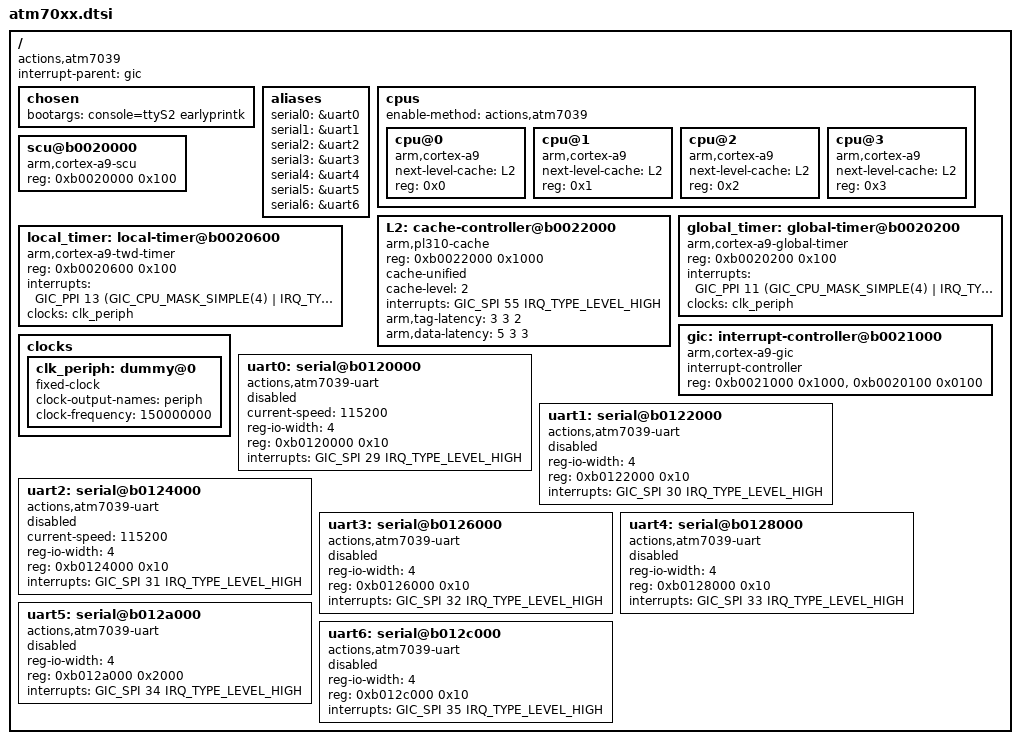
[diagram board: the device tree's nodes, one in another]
/*
 * Copyright (c) 2014 Actions Semiconductor Co., Ltd.
 *
 * Author: Yixun Lan <yixun.lan@gmail.com>
 *
 * This program is free software; you can redistribute it and/or modify
 * it under the terms of the GNU General Public License as published by
 * the Free Software Foundation; either version 2 of the License, or
 * (at your option) any later version.
 *
 * This program is distributed in the hope that it will be useful,
 * but WITHOUT ANY WARRANTY; without even the implied warranty of
 * MERCHANTABILITY or FITNESS FOR A PARTICULAR PURPOSE.  See the
 * GNU General Public License for more details.
 */

#include <dt-bindings/interrupt-controller/irq.h>
#include <dt-bindings/interrupt-controller/arm-gic.h>
#include "skeleton.dtsi"

/ {
	compatible = "actions,atm7039", "actions,atm7059";
	interrupt-parent = <&gic>;

	chosen {
		bootargs = "console=ttyS2 earlyprintk";
	};

	aliases {
		serial0 = &uart0;
		serial1 = &uart1;
		serial2 = &uart2;
		serial3 = &uart3;
		serial4 = &uart4;
		serial5 = &uart5;
		serial6 = &uart6;
	};

	cpus {
		#address-cells = <1>;
		#size-cells = <0>;
		enable-method = "actions,atm7039";

		cpu@0 {
			device_type = "cpu";
			compatible = "arm,cortex-a9";
			next-level-cache = <&L2>;
			reg = <0x0>;
		};
		cpu@1 {
			device_type = "cpu";
			compatible = "arm,cortex-a9";
			next-level-cache = <&L2>;
			reg = <0x1>;
		};
		cpu@2 {
			device_type = "cpu";
			compatible = "arm,cortex-a9";
			next-level-cache = <&L2>;
			reg = <0x2>;
		};
		cpu@3 {
			device_type = "cpu";
			compatible = "arm,cortex-a9";
			next-level-cache = <&L2>;
			reg = <0x3>;
		};
	};

	L2: cache-controller@b0022000 {
		compatible = "arm,pl310-cache";
		reg = < 0xb0022000 0x1000 >;
		cache-unified;
		cache-level = <2>;
		interrupts = < GIC_SPI 55 IRQ_TYPE_LEVEL_HIGH >;
		arm,tag-latency = <3 3 2>;
		arm,data-latency = <5 3 3>;
	};

	scu@b0020000 {
		compatible = "arm,cortex-a9-scu";
		reg = <0xb0020000 0x100>;
	};

	global_timer: global-timer@b0020200 {
		compatible = "arm,cortex-a9-global-timer";
		reg = <0xb0020200 0x100>;
		interrupts = <GIC_PPI 11 (GIC_CPU_MASK_SIMPLE(4) | IRQ_TYPE_LEVEL_HIGH)>;
		clocks = <&clk_periph>;
	};

	local_timer: local-timer@b0020600 {
		compatible = "arm,cortex-a9-twd-timer";
		reg = <0xb0020600 0x100>;
		interrupts = <GIC_PPI 13 (GIC_CPU_MASK_SIMPLE(4) | IRQ_TYPE_LEVEL_HIGH)>;
		clocks = <&clk_periph>;
	};

	gic: interrupt-controller@b0021000 {
		compatible = "arm,cortex-a9-gic";
		interrupt-controller;
		#interrupt-cells = <3>;
		reg = <0xb0021000 0x1000>,
		      <0xb0020100 0x0100>;
	};

	clocks {
		#address-cells = <1>;
		#size-cells = <0>;

		/* As long as we do not have a real clock driver us this
		 * fixed clock */
		clk_periph: dummy@0 {
			compatible = "fixed-clock";
			#clock-cells = <0>;
			clock-output-names = "periph";
			clock-frequency = <150000000>;
		};
	};

	uart0: serial@b0120000 {
		compatible = "actions,atm7039-uart";
		current-speed = <115200>;
		reg-io-width = <4>;
		reg = <0xb0120000 0x10>;
		interrupts = < GIC_SPI 29 IRQ_TYPE_LEVEL_HIGH >;
		status = "disabled";
	};

	uart1: serial@b0122000 {
		compatible = "actions,atm7039-uart";
		reg-io-width = <4>;
		reg = <0xb0122000 0x10>;
		interrupts = < GIC_SPI 30 IRQ_TYPE_LEVEL_HIGH >;
		status = "disabled";
	};

	uart2: serial@b0124000 {
		compatible = "actions,atm7039-uart";
		current-speed = <115200>;
		reg-io-width = <4>;
		reg = <0xb0124000 0x10>;
		interrupts = < GIC_SPI 31 IRQ_TYPE_LEVEL_HIGH >;
		status = "disabled";
	};

	uart3: serial@b0126000 {
		compatible = "actions,atm7039-uart";
		reg-io-width = <4>;
		reg = <0xb0126000 0x10>;
		interrupts = < GIC_SPI 32 IRQ_TYPE_LEVEL_HIGH >;
		status = "disabled";
	};

	uart4: serial@b0128000 {
		compatible = "actions,atm7039-uart";
		reg-io-width = <4>;
		reg = <0xb0128000 0x10>;
		interrupts = < GIC_SPI 33 IRQ_TYPE_LEVEL_HIGH >;
		status = "disabled";
	};

	uart5: serial@b012a000 {
		compatible = "actions,atm7039-uart";
		reg-io-width = <4>;
		reg = <0xb012a000 0x2000>;
		interrupts = < GIC_SPI 34 IRQ_TYPE_LEVEL_HIGH >;
		status = "disabled";
	};

	uart6: serial@b012c000 {
		compatible = "actions,atm7039-uart";
		reg-io-width = <4>;
		reg = <0xb012c000 0x10>;
		interrupts = < GIC_SPI 35 IRQ_TYPE_LEVEL_HIGH >;
		status = "disabled";
	};
};
